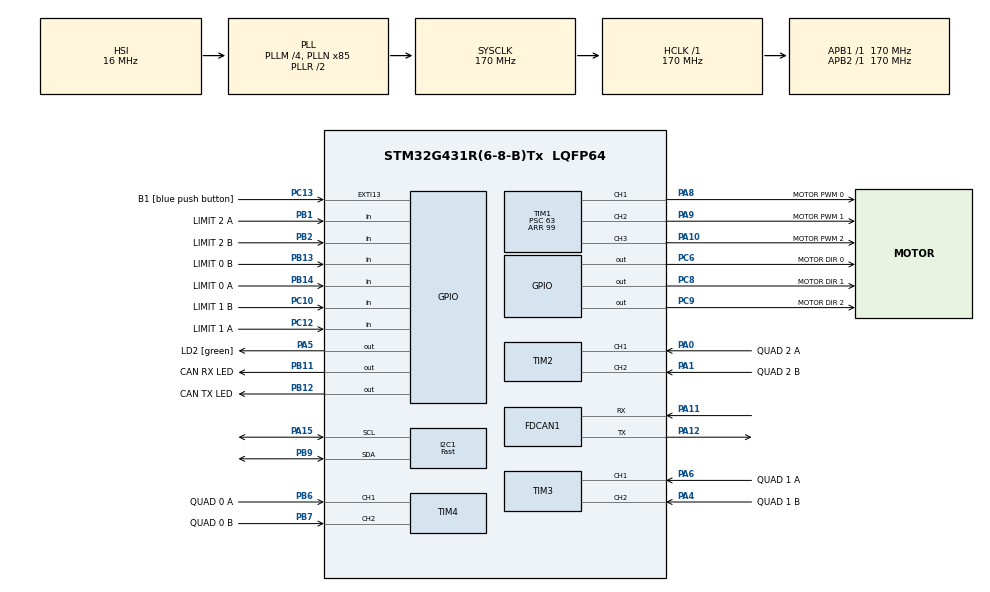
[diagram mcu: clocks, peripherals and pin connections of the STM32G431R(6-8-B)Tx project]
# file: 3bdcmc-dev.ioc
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FDCAN1.AutoRetransmission=ENABLE
FDCAN1.CalculateBaudRateNominal=999999
FDCAN1.CalculateTimeBitNominal=1000
FDCAN1.CalculateTimeQuantumNominal=11.764705882352942
FDCAN1.ClockDivider=FDCAN_CLOCK_DIV2
FDCAN1.DataSyncJumpWidth=5
FDCAN1.DataTimeSeg1=11
FDCAN1.DataTimeSeg2=5
FDCAN1.ExtFiltersNbr=3
FDCAN1.FrameFormat=FDCAN_FRAME_FD_BRS
FDCAN1.Mode=FDCAN_MODE_NORMAL
FDCAN1.NominalPrescaler=1
FDCAN1.NominalSyncJumpWidth=16
FDCAN1.NominalTimeSeg1=56
FDCAN1.NominalTimeSeg2=28
I2C1.I2C_Fall_Time=0
I2C1.I2C_Rise_Time=0
I2C1.I2C_Speed_Mode=I2C_Fast
I2C1.Timing=0x10802D9B
Mcu.Family=STM32G4
Mcu.Name=STM32G431R(6-8-B)Tx
Mcu.Package=LQFP64
NVIC.FDCAN1_IT0_IRQn=true\:0\:0\:false\:false\:true\:true\:true\:true
NVIC.I2C1_ER_IRQn=true\:0\:0\:false\:false\:true\:true\:true\:true
NVIC.I2C1_EV_IRQn=true\:0\:0\:false\:false\:true\:true\:true\:true
NVIC.PriorityGroup=NVIC_PRIORITYGROUP_4
NVIC.TIM1_BRK_TIM15_IRQn=true\:0\:0\:false\:false\:true\:true\:true\:true
NVIC.TIM1_TRG_COM_TIM17_IRQn=true\:0\:0\:false\:false\:true\:true\:true\:true
NVIC.TIM1_UP_TIM16_IRQn=true\:0\:0\:false\:false\:true\:true\:true\:true
NVIC.TIM6_DAC_IRQn=true\:0\:0\:false\:false\:true\:true\:true\:true
NVIC.TIM7_IRQn=true\:0\:0\:false\:false\:true\:true\:true\:true
PA0.GPIO_Label=QUAD 2 A
PA0.Signal=S_TIM2_CH1
PA1.GPIO_Label=QUAD 2 B
PA1.Signal=S_TIM2_CH2
PA10.GPIO_Label=MOTOR PWM 2
PA10.Signal=S_TIM1_CH3
PA11.Mode=FDCAN_Activate
PA11.Signal=FDCAN1_RX
PA12.Mode=FDCAN_Activate
PA12.Signal=FDCAN1_TX
PA13.GPIO_Label=T_SWDIO
PA13.Signal=SYS_JTMS-SWDIO
PA14.GPIO_Label=T_SWCLK
PA14.Signal=SYS_JTCK-SWCLK
PA15.Mode=I2C
PA15.Signal=I2C1_SCL
PA2.GPIO_Label=LPUART1_TX [STLINKV3E_VCP_RX]
PA2.Signal=LPUART1_TX
PA3.GPIO_Label=LPUART1_RX [STLINKV3E_VCP_TX]
PA3.Signal=LPUART1_RX
PA4.GPIO_Label=QUAD 1 B
PA4.Signal=S_TIM3_CH2
PA5.GPIO_Label=LD2 [green]
PA5.Signal=GPIO_Output
PA6.GPIO_Label=QUAD 1 A
PA6.Signal=S_TIM3_CH1
PA8.GPIO_Label=MOTOR PWM 0
PA8.Signal=S_TIM1_CH1
PA9.GPIO_Label=MOTOR PWM 1
PA9.Signal=S_TIM1_CH2
PB1.GPIO_Label=LIMIT 2 A
PB1.GPIO_PuPd=GPIO_PULLUP
PB1.Signal=GPIO_Input
PB11.GPIO_Label=CAN RX LED
PB11.Signal=GPIO_Output
PB12.GPIO_Label=CAN TX LED
PB12.Signal=GPIO_Output
PB13.GPIO_Label=LIMIT 0 B
PB13.GPIO_PuPd=GPIO_PULLUP
PB13.Signal=GPIO_Input
PB14.GPIO_Label=LIMIT 0 A
PB14.GPIO_PuPd=GPIO_PULLUP
PB14.Signal=GPIO_Input
PB2.GPIO_Label=LIMIT 2 B
PB2.GPIO_PuPd=GPIO_PULLUP
PB2.Signal=GPIO_Input
PB3.GPIO_Label=T_SWO
PB3.Signal=SYS_JTDO-SWO
PB6.GPIO_Label=QUAD 0 A
PB6.Signal=S_TIM4_CH1
PB7.GPIO_Label=QUAD 0 B
PB7.Signal=S_TIM4_CH2
PB9.Mode=I2C
PB9.Signal=I2C1_SDA
PC10.GPIO_Label=LIMIT 1 B
PC10.GPIO_PuPd=GPIO_PULLUP
PC10.Signal=GPIO_Input
PC12.GPIO_Label=LIMIT 1 A
PC12.GPIO_PuPd=GPIO_PULLUP
PC12.Signal=GPIO_Input
PC13.GPIO_Label=B1 [blue push button]
PC13.Signal=GPXTI13
PC14-OSC32_IN.GPIO_Label=RCC_OSC32_OUT
PC14-OSC32_IN.Signal=RCC_OSC32_IN
PC15-OSC32_OUT.GPIO_Label=RCC_OSC32_OUT
PC15-OSC32_OUT.Signal=RCC_OSC32_OUT
PC6.GPIO_Label=MOTOR DIR 0
PC6.Signal=GPIO_Output
PC8.GPIO_Label=MOTOR DIR 1
PC8.Signal=GPIO_Output
PC9.GPIO_Label=MOTOR DIR 2
PC9.Signal=GPIO_Output
PF0-OSC_IN.GPIO_Label=RCC_OSC_IN
PF0-OSC_IN.Signal=RCC_OSC_IN
PF1-OSC_OUT.GPIO_Label=RCC_OSC_OUT
PF1-OSC_OUT.Signal=RCC_OSC_OUT
ProjectManager.HeapSize=0x200
ProjectManager.StackSize=0x400
ProjectManager.TargetToolchain=STM32CubeIDE
RCC.ADC12Freq_Value=170000000
RCC.AHBFreq_Value=170000000
RCC.APB1Freq_Value=170000000
RCC.APB1TimFreq_Value=170000000
RCC.APB2Freq_Value=170000000
RCC.APB2TimFreq_Value=170000000
RCC.CortexFreq_Value=170000000
RCC.EXTERNAL_CLOCK_VALUE=12288000
RCC.HCLKFreq_Value=170000000
RCC.HSE_VALUE=24000000
RCC.HSI48_VALUE=48000000
RCC.HSI_VALUE=16000000
RCC.LSE_VALUE=32768
RCC.PLLM=RCC_PLLM_DIV4
RCC.PLLN=85
RCC.RTCClockSelection=RCC_RTCCLKSOURCE_LSE
RCC.SYSCLKFreq_VALUE=170000000
RCC.SYSCLKSource=RCC_SYSCLKSOURCE_PLLCLK
RCC.USBFreq_Value=170000000
RCC.VCOOutputFreq_Value=340000000
SH.S_TIM1_CH1.0=TIM1_CH1,PWM Generation1 CH1
SH.S_TIM1_CH2.0=TIM1_CH2,PWM Generation2 CH2
SH.S_TIM1_CH3.0=TIM1_CH3,PWM Generation3 CH3
SH.S_TIM2_CH1.0=TIM2_CH1,Encoder_Interface
SH.S_TIM2_CH2.0=TIM2_CH2,Encoder_Interface
SH.S_TIM3_CH1.0=TIM3_CH1,Encoder_Interface
SH.S_TIM3_CH2.0=TIM3_CH2,Encoder_Interface
SH.S_TIM4_CH1.0=TIM4_CH1,Encoder_Interface
SH.S_TIM4_CH2.0=TIM4_CH2,Encoder_Interface
TIM1.Channel-PWM\ Generation1\ CH1=TIM_CHANNEL_1
TIM1.Channel-PWM\ Generation2\ CH2=TIM_CHANNEL_2
TIM1.Channel-PWM\ Generation3\ CH3=TIM_CHANNEL_3
TIM1.PeriodNoDither=99
TIM1.Prescaler=63
TIM15.PeriodNoDither=54580
TIM15.Prescaler=512
TIM16.PeriodNoDither=54580
TIM16.Prescaler=512
TIM17.PeriodNoDither=54580
TIM17.Prescaler=512
TIM6.PeriodNoDither=58333
TIM6.Prescaler=119
VP_SYS_VS_DBSignals.Mode=DisableDeadBatterySignals
VP_TIM15_VS_ClockSourceINT.Mode=Internal
VP_TIM16_VS_ClockSourceINT.Mode=Enable_Timer
VP_TIM17_VS_ClockSourceINT.Mode=Enable_Timer
VP_TIM6_VS_ClockSourceINT.Mode=Enable_Timer
VP_TIM7_VS_ClockSourceINT.Mode=Enable_Timer
board=NUCLEO-G431RB

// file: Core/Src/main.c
/* USER CODE BEGIN Header */
/**
  ******************************************************************************
  * @file           : main.c
  * @brief          : Main program body
  ******************************************************************************
  * @attention
  *
  * Copyright (c) 2024 STMicroelectronics.
  * All rights reserved.
  *
  * This software is licensed under terms that can be found in the LICENSE file
  * in the root directory of this software component.
  * If no LICENSE file comes with this software, it is provided AS-IS.
  *
  ******************************************************************************
  */
/* USER CODE END Header */
#include "main.h"

FDCAN_HandleTypeDef hfdcan1;

I2C_HandleTypeDef hi2c1;

TIM_HandleTypeDef htim1;
TIM_HandleTypeDef htim2;
TIM_HandleTypeDef htim3;
TIM_HandleTypeDef htim4;
TIM_HandleTypeDef htim6;
TIM_HandleTypeDef htim7;
TIM_HandleTypeDef htim15;
TIM_HandleTypeDef htim16;
TIM_HandleTypeDef htim17;

void SystemClock_Config(void);
static void MX_GPIO_Init(void);
static void MX_FDCAN1_Init(void);
static void MX_I2C1_Init(void);
static void MX_TIM1_Init(void);
static void MX_TIM2_Init(void);
static void MX_TIM3_Init(void);
static void MX_TIM4_Init(void);
static void MX_TIM6_Init(void);
static void MX_TIM7_Init(void);
static void MX_TIM15_Init(void);
static void MX_TIM16_Init(void);
static void MX_TIM17_Init(void);

int main(void)
{

  /* MCU Configuration--------------------------------------------------------*/

  /* Reset of all peripherals, Initializes the Flash interface and the Systick. */
  HAL_Init();

  /* Configure the system clock */
  SystemClock_Config();

  /* Initialize all configured peripherals */
  MX_GPIO_Init();
  MX_FDCAN1_Init();
  MX_I2C1_Init();
  MX_TIM1_Init();
  MX_TIM2_Init();
  MX_TIM3_Init();
  MX_TIM4_Init();
  MX_TIM6_Init();
  MX_TIM7_Init();
  MX_TIM15_Init();
  MX_TIM16_Init();
  MX_TIM17_Init();
  /* USER CODE BEGIN 2 */
  HAL_FDCAN_ConfigTxDelayCompensation(&hfdcan1, 13, 1);
  HAL_FDCAN_EnableTxDelayCompensation(&hfdcan1);
  HAL_PostInit();

  /* USER CODE END 2 */

  /* Infinite loop */
  while (1)
  {

  }
}

void SystemClock_Config(void)
{
  RCC_OscInitTypeDef RCC_OscInitStruct = {0};
  RCC_ClkInitTypeDef RCC_ClkInitStruct = {0};

  /** Configure the main internal regulator output voltage
  */
  HAL_PWREx_ControlVoltageScaling(PWR_REGULATOR_VOLTAGE_SCALE1_BOOST);

  /** Initializes the RCC Oscillators according to the specified parameters
  * in the RCC_OscInitTypeDef structure.
  */
  RCC_OscInitStruct.OscillatorType = RCC_OSCILLATORTYPE_HSI;
  RCC_OscInitStruct.HSIState = RCC_HSI_ON;
  RCC_OscInitStruct.HSICalibrationValue = RCC_HSICALIBRATION_DEFAULT;
  RCC_OscInitStruct.PLL.PLLState = RCC_PLL_ON;
  RCC_OscInitStruct.PLL.PLLSource = RCC_PLLSOURCE_HSI;
  RCC_OscInitStruct.PLL.PLLM = RCC_PLLM_DIV4;
  RCC_OscInitStruct.PLL.PLLN = 85;
  RCC_OscInitStruct.PLL.PLLP = RCC_PLLP_DIV2;
  RCC_OscInitStruct.PLL.PLLQ = RCC_PLLQ_DIV2;
  RCC_OscInitStruct.PLL.PLLR = RCC_PLLR_DIV2;
  if (HAL_RCC_OscConfig(&RCC_OscInitStruct) != HAL_OK)
  {
    Error_Handler();
  }

  /** Initializes the CPU, AHB and APB buses clocks
  */
  RCC_ClkInitStruct.ClockType = RCC_CLOCKTYPE_HCLK|RCC_CLOCKTYPE_SYSCLK
                              |RCC_CLOCKTYPE_PCLK1|RCC_CLOCKTYPE_PCLK2;
  RCC_ClkInitStruct.SYSCLKSource = RCC_SYSCLKSOURCE_PLLCLK;
  RCC_ClkInitStruct.AHBCLKDivider = RCC_SYSCLK_DIV1;
  RCC_ClkInitStruct.APB1CLKDivider = RCC_HCLK_DIV1;
  RCC_ClkInitStruct.APB2CLKDivider = RCC_HCLK_DIV1;

  if (HAL_RCC_ClockConfig(&RCC_ClkInitStruct, FLASH_LATENCY_4) != HAL_OK)
  {
    Error_Handler();
  }
}

static void MX_FDCAN1_Init(void)
{

  hfdcan1.Instance = FDCAN1;
  hfdcan1.Init.ClockDivider = FDCAN_CLOCK_DIV2;
  hfdcan1.Init.FrameFormat = FDCAN_FRAME_FD_BRS;
  hfdcan1.Init.Mode = FDCAN_MODE_NORMAL;
  hfdcan1.Init.AutoRetransmission = ENABLE;
  hfdcan1.Init.TransmitPause = DISABLE;
  hfdcan1.Init.ProtocolException = DISABLE;
  hfdcan1.Init.NominalPrescaler = 1;
  hfdcan1.Init.NominalSyncJumpWidth = 16;
  hfdcan1.Init.NominalTimeSeg1 = 56;
  hfdcan1.Init.NominalTimeSeg2 = 28;
  hfdcan1.Init.DataPrescaler = 1;
  hfdcan1.Init.DataSyncJumpWidth = 5;
  hfdcan1.Init.DataTimeSeg1 = 11;
  hfdcan1.Init.DataTimeSeg2 = 5;
  hfdcan1.Init.StdFiltersNbr = 0;
  hfdcan1.Init.ExtFiltersNbr = 3;
  hfdcan1.Init.TxFifoQueueMode = FDCAN_TX_FIFO_OPERATION;
  if (HAL_FDCAN_Init(&hfdcan1) != HAL_OK)
  {
    Error_Handler();
  }

}

static void MX_I2C1_Init(void)
{

  hi2c1.Instance = I2C1;
  hi2c1.Init.Timing = 0x10802D9B;
  hi2c1.Init.OwnAddress1 = 0;
  hi2c1.Init.AddressingMode = I2C_ADDRESSINGMODE_7BIT;
  hi2c1.Init.DualAddressMode = I2C_DUALADDRESS_DISABLE;
  hi2c1.Init.OwnAddress2 = 0;
  hi2c1.Init.OwnAddress2Masks = I2C_OA2_NOMASK;
  hi2c1.Init.GeneralCallMode = I2C_GENERALCALL_DISABLE;
  hi2c1.Init.NoStretchMode = I2C_NOSTRETCH_DISABLE;
  if (HAL_I2C_Init(&hi2c1) != HAL_OK)
  {
    Error_Handler();
  }

  /** Configure Analogue filter
  */
  if (HAL_I2CEx_ConfigAnalogFilter(&hi2c1, I2C_ANALOGFILTER_ENABLE) != HAL_OK)
  {
    Error_Handler();
  }

  /** Configure Digital filter
  */
  if (HAL_I2CEx_ConfigDigitalFilter(&hi2c1, 0) != HAL_OK)
  {
    Error_Handler();
  }

}

static void MX_TIM1_Init(void)
{

  TIM_MasterConfigTypeDef sMasterConfig = {0};
  TIM_OC_InitTypeDef sConfigOC = {0};
  TIM_BreakDeadTimeConfigTypeDef sBreakDeadTimeConfig = {0};

  htim1.Instance = TIM1;
  htim1.Init.Prescaler = 63;
  htim1.Init.CounterMode = TIM_COUNTERMODE_UP;
  htim1.Init.Period = 99;
  htim1.Init.ClockDivision = TIM_CLOCKDIVISION_DIV1;
  htim1.Init.RepetitionCounter = 0;
  htim1.Init.AutoReloadPreload = TIM_AUTORELOAD_PRELOAD_DISABLE;
  if (HAL_TIM_PWM_Init(&htim1) != HAL_OK)
  {
    Error_Handler();
  }
  sMasterConfig.MasterOutputTrigger = TIM_TRGO_RESET;
  sMasterConfig.MasterOutputTrigger2 = TIM_TRGO2_RESET;
  sMasterConfig.MasterSlaveMode = TIM_MASTERSLAVEMODE_DISABLE;
  if (HAL_TIMEx_MasterConfigSynchronization(&htim1, &sMasterConfig) != HAL_OK)
  {
    Error_Handler();
  }
  sConfigOC.OCMode = TIM_OCMODE_PWM1;
  sConfigOC.Pulse = 0;
  sConfigOC.OCPolarity = TIM_OCPOLARITY_HIGH;
  sConfigOC.OCNPolarity = TIM_OCNPOLARITY_HIGH;
  sConfigOC.OCFastMode = TIM_OCFAST_DISABLE;
  sConfigOC.OCIdleState = TIM_OCIDLESTATE_RESET;
  sConfigOC.OCNIdleState = TIM_OCNIDLESTATE_RESET;
  if (HAL_TIM_PWM_ConfigChannel(&htim1, &sConfigOC, TIM_CHANNEL_1) != HAL_OK)
  {
    Error_Handler();
  }
  if (HAL_TIM_PWM_ConfigChannel(&htim1, &sConfigOC, TIM_CHANNEL_2) != HAL_OK)
  {
    Error_Handler();
  }
  if (HAL_TIM_PWM_ConfigChannel(&htim1, &sConfigOC, TIM_CHANNEL_3) != HAL_OK)
  {
    Error_Handler();
  }
  sBreakDeadTimeConfig.OffStateRunMode = TIM_OSSR_DISABLE;
  sBreakDeadTimeConfig.OffStateIDLEMode = TIM_OSSI_DISABLE;
  sBreakDeadTimeConfig.LockLevel = TIM_LOCKLEVEL_OFF;
  sBreakDeadTimeConfig.DeadTime = 0;
  sBreakDeadTimeConfig.BreakState = TIM_BREAK_DISABLE;
  sBreakDeadTimeConfig.BreakPolarity = TIM_BREAKPOLARITY_HIGH;
  sBreakDeadTimeConfig.BreakFilter = 0;
  sBreakDeadTimeConfig.BreakAFMode = TIM_BREAK_AFMODE_INPUT;
  sBreakDeadTimeConfig.Break2State = TIM_BREAK2_DISABLE;
  sBreakDeadTimeConfig.Break2Polarity = TIM_BREAK2POLARITY_HIGH;
  sBreakDeadTimeConfig.Break2Filter = 0;
  sBreakDeadTimeConfig.Break2AFMode = TIM_BREAK_AFMODE_INPUT;
  sBreakDeadTimeConfig.AutomaticOutput = TIM_AUTOMATICOUTPUT_DISABLE;
  if (HAL_TIMEx_ConfigBreakDeadTime(&htim1, &sBreakDeadTimeConfig) != HAL_OK)
  {
    Error_Handler();
  }
  HAL_TIM_MspPostInit(&htim1);

}

static void MX_TIM2_Init(void)
{

  TIM_Encoder_InitTypeDef sConfig = {0};
  TIM_MasterConfigTypeDef sMasterConfig = {0};

  htim2.Instance = TIM2;
  htim2.Init.Prescaler = 0;
  htim2.Init.CounterMode = TIM_COUNTERMODE_UP;
  htim2.Init.Period = 4294967295;
  htim2.Init.ClockDivision = TIM_CLOCKDIVISION_DIV1;
  htim2.Init.AutoReloadPreload = TIM_AUTORELOAD_PRELOAD_DISABLE;
  sConfig.EncoderMode = TIM_ENCODERMODE_TI1;
  sConfig.IC1Polarity = TIM_ICPOLARITY_RISING;
  sConfig.IC1Selection = TIM_ICSELECTION_DIRECTTI;
  sConfig.IC1Prescaler = TIM_ICPSC_DIV1;
  sConfig.IC1Filter = 0;
  sConfig.IC2Polarity = TIM_ICPOLARITY_RISING;
  sConfig.IC2Selection = TIM_ICSELECTION_DIRECTTI;
  sConfig.IC2Prescaler = TIM_ICPSC_DIV1;
  sConfig.IC2Filter = 0;
  if (HAL_TIM_Encoder_Init(&htim2, &sConfig) != HAL_OK)
  {
    Error_Handler();
  }
  sMasterConfig.MasterOutputTrigger = TIM_TRGO_RESET;
  sMasterConfig.MasterSlaveMode = TIM_MASTERSLAVEMODE_DISABLE;
  if (HAL_TIMEx_MasterConfigSynchronization(&htim2, &sMasterConfig) != HAL_OK)
  {
    Error_Handler();
  }

}

static void MX_TIM3_Init(void)
{

  TIM_Encoder_InitTypeDef sConfig = {0};
  TIM_MasterConfigTypeDef sMasterConfig = {0};

  htim3.Instance = TIM3;
  htim3.Init.Prescaler = 0;
  htim3.Init.CounterMode = TIM_COUNTERMODE_UP;
  htim3.Init.Period = 65535;
  htim3.Init.ClockDivision = TIM_CLOCKDIVISION_DIV1;
  htim3.Init.AutoReloadPreload = TIM_AUTORELOAD_PRELOAD_DISABLE;
  sConfig.EncoderMode = TIM_ENCODERMODE_TI1;
  sConfig.IC1Polarity = TIM_ICPOLARITY_RISING;
  sConfig.IC1Selection = TIM_ICSELECTION_DIRECTTI;
  sConfig.IC1Prescaler = TIM_ICPSC_DIV1;
  sConfig.IC1Filter = 0;
  sConfig.IC2Polarity = TIM_ICPOLARITY_RISING;
  sConfig.IC2Selection = TIM_ICSELECTION_DIRECTTI;
  sConfig.IC2Prescaler = TIM_ICPSC_DIV1;
  sConfig.IC2Filter = 0;
  if (HAL_TIM_Encoder_Init(&htim3, &sConfig) != HAL_OK)
  {
    Error_Handler();
  }
  sMasterConfig.MasterOutputTrigger = TIM_TRGO_RESET;
  sMasterConfig.MasterSlaveMode = TIM_MASTERSLAVEMODE_DISABLE;
  if (HAL_TIMEx_MasterConfigSynchronization(&htim3, &sMasterConfig) != HAL_OK)
  {
    Error_Handler();
  }

}

static void MX_TIM4_Init(void)
{

  TIM_Encoder_InitTypeDef sConfig = {0};
  TIM_MasterConfigTypeDef sMasterConfig = {0};

  htim4.Instance = TIM4;
  htim4.Init.Prescaler = 0;
  htim4.Init.CounterMode = TIM_COUNTERMODE_UP;
  htim4.Init.Period = 65535;
  htim4.Init.ClockDivision = TIM_CLOCKDIVISION_DIV1;
  htim4.Init.AutoReloadPreload = TIM_AUTORELOAD_PRELOAD_DISABLE;
  sConfig.EncoderMode = TIM_ENCODERMODE_TI1;
  sConfig.IC1Polarity = TIM_ICPOLARITY_RISING;
  sConfig.IC1Selection = TIM_ICSELECTION_DIRECTTI;
  sConfig.IC1Prescaler = TIM_ICPSC_DIV1;
  sConfig.IC1Filter = 0;
  sConfig.IC2Polarity = TIM_ICPOLARITY_RISING;
  sConfig.IC2Selection = TIM_ICSELECTION_DIRECTTI;
  sConfig.IC2Prescaler = TIM_ICPSC_DIV1;
  sConfig.IC2Filter = 0;
  if (HAL_TIM_Encoder_Init(&htim4, &sConfig) != HAL_OK)
  {
    Error_Handler();
  }
  sMasterConfig.MasterOutputTrigger = TIM_TRGO_RESET;
  sMasterConfig.MasterSlaveMode = TIM_MASTERSLAVEMODE_DISABLE;
  if (HAL_TIMEx_MasterConfigSynchronization(&htim4, &sMasterConfig) != HAL_OK)
  {
    Error_Handler();
  }

}

static void MX_TIM6_Init(void)
{

  TIM_MasterConfigTypeDef sMasterConfig = {0};

  htim6.Instance = TIM6;
  htim6.Init.Prescaler = 119;
  htim6.Init.CounterMode = TIM_COUNTERMODE_UP;
  htim6.Init.Period = 58333;
  htim6.Init.AutoReloadPreload = TIM_AUTORELOAD_PRELOAD_DISABLE;
  if (HAL_TIM_Base_Init(&htim6) != HAL_OK)
  {
    Error_Handler();
  }
  sMasterConfig.MasterOutputTrigger = TIM_TRGO_RESET;
  sMasterConfig.MasterSlaveMode = TIM_MASTERSLAVEMODE_DISABLE;
  if (HAL_TIMEx_MasterConfigSynchronization(&htim6, &sMasterConfig) != HAL_OK)
  {
    Error_Handler();
  }

}

static void MX_TIM7_Init(void)
{

  TIM_MasterConfigTypeDef sMasterConfig = {0};

  htim7.Instance = TIM7;
  htim7.Init.Prescaler = 169;
  htim7.Init.CounterMode = TIM_COUNTERMODE_UP;
  htim7.Init.Period = 65535;
  htim7.Init.AutoReloadPreload = TIM_AUTORELOAD_PRELOAD_DISABLE;
  if (HAL_TIM_Base_Init(&htim7) != HAL_OK)
  {
    Error_Handler();
  }
  sMasterConfig.MasterOutputTrigger = TIM_TRGO_RESET;
  sMasterConfig.MasterSlaveMode = TIM_MASTERSLAVEMODE_DISABLE;
  if (HAL_TIMEx_MasterConfigSynchronization(&htim7, &sMasterConfig) != HAL_OK)
  {
    Error_Handler();
  }

}

static void MX_TIM15_Init(void)
{

  TIM_ClockConfigTypeDef sClockSourceConfig = {0};
  TIM_MasterConfigTypeDef sMasterConfig = {0};

  htim15.Instance = TIM15;
  htim15.Init.Prescaler = 512;
  htim15.Init.CounterMode = TIM_COUNTERMODE_UP;
  htim15.Init.Period = 54580;
  htim15.Init.ClockDivision = TIM_CLOCKDIVISION_DIV1;
  htim15.Init.RepetitionCounter = 0;
  htim15.Init.AutoReloadPreload = TIM_AUTORELOAD_PRELOAD_DISABLE;
  if (HAL_TIM_Base_Init(&htim15) != HAL_OK)
  {
    Error_Handler();
  }
  sClockSourceConfig.ClockSource = TIM_CLOCKSOURCE_INTERNAL;
  if (HAL_TIM_ConfigClockSource(&htim15, &sClockSourceConfig) != HAL_OK)
  {
    Error_Handler();
  }
  sMasterConfig.MasterOutputTrigger = TIM_TRGO_RESET;
  sMasterConfig.MasterSlaveMode = TIM_MASTERSLAVEMODE_DISABLE;
  if (HAL_TIMEx_MasterConfigSynchronization(&htim15, &sMasterConfig) != HAL_OK)
  {
    Error_Handler();
  }

}

static void MX_TIM16_Init(void)
{

  htim16.Instance = TIM16;
  htim16.Init.Prescaler = 512;
  htim16.Init.CounterMode = TIM_COUNTERMODE_UP;
  htim16.Init.Period = 54580;
  htim16.Init.ClockDivision = TIM_CLOCKDIVISION_DIV1;
  htim16.Init.RepetitionCounter = 0;
  htim16.Init.AutoReloadPreload = TIM_AUTORELOAD_PRELOAD_DISABLE;
  if (HAL_TIM_Base_Init(&htim16) != HAL_OK)
  {
    Error_Handler();
  }

}

static void MX_TIM17_Init(void)
{

  htim17.Instance = TIM17;
  htim17.Init.Prescaler = 512;
  htim17.Init.CounterMode = TIM_COUNTERMODE_UP;
  htim17.Init.Period = 54580;
  htim17.Init.ClockDivision = TIM_CLOCKDIVISION_DIV1;
  htim17.Init.RepetitionCounter = 0;
  htim17.Init.AutoReloadPreload = TIM_AUTORELOAD_PRELOAD_DISABLE;
  if (HAL_TIM_Base_Init(&htim17) != HAL_OK)
  {
    Error_Handler();
  }

}

static void MX_GPIO_Init(void)
{
  GPIO_InitTypeDef GPIO_InitStruct = {0};

  /* GPIO Ports Clock Enable */
  __HAL_RCC_GPIOC_CLK_ENABLE();
  __HAL_RCC_GPIOF_CLK_ENABLE();
  __HAL_RCC_GPIOA_CLK_ENABLE();
  __HAL_RCC_GPIOB_CLK_ENABLE();

  /*Configure GPIO pin Output Level */
  HAL_GPIO_WritePin(LD2_GPIO_Port, LD2_Pin, GPIO_PIN_RESET);

  /*Configure GPIO pin Output Level */
  HAL_GPIO_WritePin(GPIOB, CAN_RX_LED_Pin|CAN_TX_LED_Pin, GPIO_PIN_RESET);

  /*Configure GPIO pin Output Level */
  HAL_GPIO_WritePin(GPIOC, MOTOR_DIR_0_Pin|MOTOR_DIR_1_Pin|MOTOR_DIR_2_Pin, GPIO_PIN_RESET);

  /*Configure GPIO pin : B1_Pin */
  GPIO_InitStruct.Pin = B1_Pin;
  GPIO_InitStruct.Mode = GPIO_MODE_IT_RISING;
  GPIO_InitStruct.Pull = GPIO_NOPULL;
  HAL_GPIO_Init(B1_GPIO_Port, &GPIO_InitStruct);

  /*Configure GPIO pins : LPUART1_TX_Pin LPUART1_RX_Pin */
  GPIO_InitStruct.Pin = LPUART1_TX_Pin|LPUART1_RX_Pin;
  GPIO_InitStruct.Mode = GPIO_MODE_AF_PP;
  GPIO_InitStruct.Pull = GPIO_NOPULL;
  GPIO_InitStruct.Speed = GPIO_SPEED_FREQ_LOW;
  GPIO_InitStruct.Alternate = GPIO_AF12_LPUART1;
  HAL_GPIO_Init(GPIOA, &GPIO_InitStruct);

  /*Configure GPIO pin : LD2_Pin */
  GPIO_InitStruct.Pin = LD2_Pin;
  GPIO_InitStruct.Mode = GPIO_MODE_OUTPUT_PP;
  GPIO_InitStruct.Pull = GPIO_NOPULL;
  GPIO_InitStruct.Speed = GPIO_SPEED_FREQ_LOW;
  HAL_GPIO_Init(LD2_GPIO_Port, &GPIO_InitStruct);

  /*Configure GPIO pins : LIMIT_2_A_Pin LIMIT_2_B_Pin LIMIT_0_B_Pin LIMIT_0_A_Pin */
  GPIO_InitStruct.Pin = LIMIT_2_A_Pin|LIMIT_2_B_Pin|LIMIT_0_B_Pin|LIMIT_0_A_Pin;
  GPIO_InitStruct.Mode = GPIO_MODE_INPUT;
  GPIO_InitStruct.Pull = GPIO_PULLUP;
  HAL_GPIO_Init(GPIOB, &GPIO_InitStruct);

  /*Configure GPIO pins : CAN_RX_LED_Pin CAN_TX_LED_Pin */
  GPIO_InitStruct.Pin = CAN_RX_LED_Pin|CAN_TX_LED_Pin;
  GPIO_InitStruct.Mode = GPIO_MODE_OUTPUT_PP;
  GPIO_InitStruct.Pull = GPIO_NOPULL;
  GPIO_InitStruct.Speed = GPIO_SPEED_FREQ_LOW;
  HAL_GPIO_Init(GPIOB, &GPIO_InitStruct);

  /*Configure GPIO pins : MOTOR_DIR_0_Pin MOTOR_DIR_1_Pin MOTOR_DIR_2_Pin */
  GPIO_InitStruct.Pin = MOTOR_DIR_0_Pin|MOTOR_DIR_1_Pin|MOTOR_DIR_2_Pin;
  GPIO_InitStruct.Mode = GPIO_MODE_OUTPUT_PP;
  GPIO_InitStruct.Pull = GPIO_NOPULL;
  GPIO_InitStruct.Speed = GPIO_SPEED_FREQ_LOW;
  HAL_GPIO_Init(GPIOC, &GPIO_InitStruct);

  /*Configure GPIO pins : LIMIT_1_B_Pin LIMIT_1_A_Pin */
  GPIO_InitStruct.Pin = LIMIT_1_B_Pin|LIMIT_1_A_Pin;
  GPIO_InitStruct.Mode = GPIO_MODE_INPUT;
  GPIO_InitStruct.Pull = GPIO_PULLUP;
  HAL_GPIO_Init(GPIOC, &GPIO_InitStruct);

}

void Error_Handler(void)
{
  __disable_irq();
  while (1)
  {
  }
}
